# RZN2H register map
Vendor: Renesas Electronics Corporation; Series: RZN; File version: 1.00.00
CPU: other r0p0, little endian, MPU, no FPU, VTOR, 4 interrupt priority bits, 624 interrupts
Registers are 32-bit, read-write, reset 0x0 unless marked. A register's access mark holds for its fields unless they carry their own. Offsets are from the block's base; [hi:lo] are bit positions; {n}, {i} and the like mark numbered series.

## HDSLD0 — HIPERFACE DSL for Drive Interface Unit 0
Base 0x90200000
Same registers: HDSLD{n} {0x90200000+0x10000*n} (n=1..11), HDSLD12 0x90300000, HDSLD13 0x90310000, HDSLD14 0x90320000, HDSLD15 0x90330000
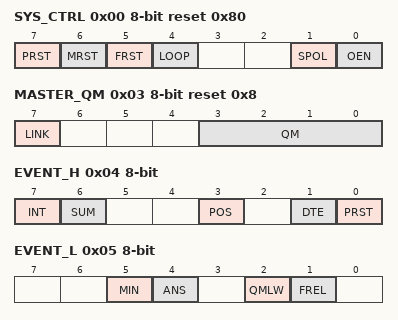
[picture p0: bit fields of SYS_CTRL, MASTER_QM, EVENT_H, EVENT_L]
0x00 SYS_CTRL 8-bit reset 0x80 — System Control Register
  [7] PRST — Protocol reset
    0=Normal protocol action; 1=A forced reset of the protocol status will be initiated. If the bit is cleared, a restart of the connection is triggered.
  [6] MRST — Messages reset
    0=Normal parameters channel action; 1=The parameters channel is reset. Current short and long messages are discarded.
  [5] FRST — Pipeline FIFO, reset
    0=Normal FIFO access; 1=The FIFO is reset. Data is not stored and cannot be read.
  [4] LOOP — Test drive interface
  [1] SPOL — Polarity of the synchronization pulse
    0=The SYNC trailing edge is used; 1=The SYNC leading edge is used
  [0] OEN — Activation of the output
    0=The impedance of the DSL cable is high; 1=The DSL cables are activated for output to the DSL Slave
0x01 SYNC_CTRL 8-bit wo — Synchronization Control Register
  [7:0] ES — External synchronization
    0=Position sampling during free running at the shortest cycle time; other=Others (Position sampling with the SYNC input synchronized. The value from ES determines the number of position samplings carried out in one SYNC cycle. The user must match the number of samplings per cycle to the shortest frame length.)
0x03 MASTER_QM 8-bit ro reset 0x8 — Quality Monitoring Register
  [7] LINK — DSL protocol connection status
    0=No connection present or connection error due to a communications error; 1=Protocol connection between DSL Master and Slave was established
  [3:0] QM — Quality monitoring bits
0x04 EVENT_H 8-bit — High Byte Event Register
  [7] INT ro — Interrupt status
    0=No interrupt in DSL Master; 1=DSL Master interrupt occurred
  [6] SUM — Remote event monitoring
    0=All DSL Slave events are cleared; 1=The DSL Slave has signaled an event and the summary mask is set accordingly
  [3] POS — Estimator turned on
    0=The data for the fast position was correctly transmitted; 1=Fast position data consistency error. The fast position read through drive interface is supplied by the estimator.
  [1] DTE — Estimator deviation threshold error
    0=Current value of deviation smaller than the specified maximum; 1=Current value of deviation greater than the specified maximum
  [0] PRST — Protocol reset warning
    0=Normal protocol action; 1=The forced protocol reset was triggered
0x05 EVENT_L 8-bit — Low Byte Event Register
  [5] MIN — Message initialization
    0=No acknowledgment for the initialization received; 1=An acknowledgment was received from the Slave for the initialization of a message
  [4] ANS — Erroneous answer to "long message"
    0=The last answers to "long messages" were error-free; 1=An error occurred during the answer to a long message. The effectiveness of the previous transaction is not known.
  [2] QMLW — Quality monitoring low-value warning
    0=Quality monitoring value greater than or equal to "14"; 1=Quality monitoring value below "14"
  [1] FREL — Channel free for "long message"
    0=No "long message" can be sent; 1=A "long message" can be sent on the Parameters Channel
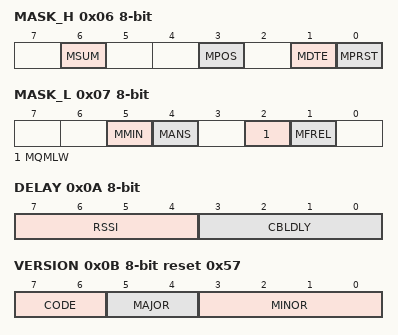
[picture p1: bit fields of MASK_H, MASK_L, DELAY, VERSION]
0x06 MASK_H 8-bit wo — High Byte Event Mask Register
  [6] MSUM — Mask for remote event monitoring
    0=DSL Slave events that are masked in the SUMMARY register do not set the interrupt signal; 1=DSL Slave events that are masked in the SUMMARY register set the interrupt signal
  [3] MPOS — Mask for fast position error
    0=An error in the fast position does not set the interrupt signal; 1=An error in the fast position sets the interrupt signal
  [1] MDTE — Mask for estimator deviation threshold error warning
    0=A high estimator deviation threshold error value does not set the interrupt signal; 1=A high estimator deviation threshold error value sets the interrupt signal
  [0] MPRST — Mask for protocol reset warning
    0=A protocol reset does not set the interrupt signal; 1=A protocol reset sets the interrupt signal
0x07 MASK_L 8-bit wo — Low Byte Event Mask Register
  [5] MMIN — Mask for message initialization confirmation
    0=The acknowledgment for the initialization of a DSL Slave message does not set the interrupt signal; 1=The acknowledgment for the initialization of a DSL Slave message sets the interrupt signal
  [4] MANS — Mask for erroneous answer to "long message"
    0=A transmission error during the answer to a long message does not set the interrupt signal; 1=A transmission error during the answer to a long message sets the interrupt signal
  [2] MQMLW — Mask for low-quality monitoring value warning
    0=A low-quality monitoring value does not set the interrupt signal; 1=A low-quality monitoring value sets the interrupt signal
  [1] MFREL — Mask for "channel free for "long message""
    0=If a "long message" can be sent on the Parameters Channel, the interrupt signal is not set; 1=If a "long message" can be sent on the Parameters Channel, the interrupt signal is set
0x08 MASK_SUM 8-bit wo — Summary Mask Register
  [7:0] MSUM — Mask for status summary bits
    0=In the set status, the corresponding status summary bit does not set the SUM event monitoring and the interrupt signal; 1=In the set status, the corresponding status summary bit sets the SUM event monitoring and the interrupt signal
0x09 EDGES 8-bit ro — Edge Register
  [7:0] EDGES — Identification of edges in the cable signal
0x0A DELAY 8-bit ro — Run Time Delay Register
  [7:4] RSSI — Indication of the received signal strength
  [3:0] CBLDLY — 4-bit value for cable delay
0x0B VERSION 8-bit ro reset 0x57
  [7:6] CODE — Type of module
    1=DSL Master; other=Others (Reserved)
  [5:4] MAJOR — Major release number
  [3:0] MINOR — Minor release number
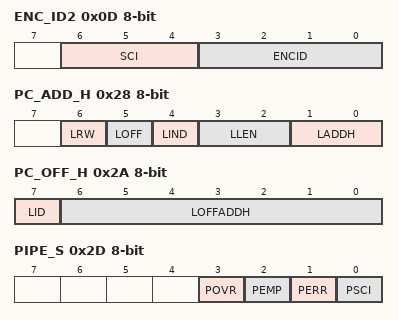
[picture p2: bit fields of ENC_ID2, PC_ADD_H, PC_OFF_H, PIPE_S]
0x0D ENC_ID2 8-bit ro — Encoder ID 2 Register
  [6:4] SCI — Indication of special characters
  [3:0] ENCID — Encoder designation code bit 19 to bit 16
0x0E ENC_ID1 8-bit ro — Encoder ID 1 Register
  [7:0] ENCID — Encoder designation code, byte n
0x0F ENC_ID0 8-bit ro — Encoder ID 0 Register
  [7:0] ENCID — Encoder designation code, byte n
0x10 POS4 8-bit ro — Fast Position Byte 4 Register
  [7:0] POS — Fast position, byte n
0x11 POS3 8-bit ro — Fast Position Byte 3 Register
  [7:0] POS — Fast position, byte n
0x12 POS2 8-bit ro — Fast Position Byte 2 Register
  [7:0] POS — Fast position, byte n
0x13 POS1 8-bit ro — Fast Position Byte 1 Register
  [7:0] POS — Fast position, byte n
0x14 POS0 8-bit ro — Fast Position Byte 0 Register
  [7:0] POS — Fast position, byte n
0x15 VEL2 8-bit ro — Speed Byte 2 Register
  [7:0] VEL — Speed, byte n
0x16 VEL1 8-bit ro — Speed Byte 1 Register
  [7:0] VEL — Speed, byte n
0x17 VEL0 8-bit ro — Speed Byte 0 Register
  [7:0] VEL — Speed, byte n
0x18 MIR_SUM 8-bit ro — Mirror Status Summary Register
  [7:0] SUM — Status summary bit
{0x20+i} PC_BUF{i} (i=0..7) 8-bit — Parameter Channel Buffer {i} Register
  [7:0] PCBUF — Parameter Channel, byte n
0x28 PC_ADD_H 8-bit — High Byte Long Message Address Register
  [6] LRW wo — Long message, read/write mode
    0="long message" write operation; 1="long message" read operation
  [5] LOFF — Long message addressing mode/long message error
    0=Write access: Addressing of "long message" without offset. The offset value from the PCOFFn registers is not used. Read access: The last "long message" was correctly processed.; 1=Write access: Offset addressing of "long message". The offset value from the PCOFFn registers is used in the resource of the selected database entry as a sub-address. Read access: The last "long message" caused an error.
  [4] LIND wo — Indirect addressing of long messages
    0=Direct addressing of "long messages". The operation affects the database entry given in the current address.; 1=Indirect addressing of "long messages". During this operation, the stored address content in the given database entry is evaluated.
  [3:2] LLEN wo — Data length of the "long message"
    0=No data bytes; 1=2 data bytes; 2=4 data bytes; 3=8 data bytes
  [1:0] LADDH wo — Long message address, bit 9 to bit 8
0x29 PC_ADD_L 8-bit wo — Low Byte Long Message Address Register
  [7:0] LADDL — Long message address, bit 7 to bit 0
0x2A PC_OFF_H 8-bit — High Byte Long Message Address Offset Register
  [7] LID ro — Long message identification
  [6:0] LOFFADDH wo — Long message offset value, bit 14 to bit 8
0x2B PC_OFF_L 8-bit wo — Low Byte Long Message Address Offset Register
  [7:0] LOFFADDL — Long message offset value, bit 7 to bit 0
0x2C PC_CTRL 8-bit wo — Parameter Channel Control Register
  [0] LSTA — Control of the long message start
    0=No effect; 1=A "long message" transaction is started with the values currently stored in the "long message" registers
0x2D PIPE_S 8-bit ro — SensorHub Channel Status Register
  [3] POVR — SensorHub Channel overflow
    0=The capacity of the FIFO buffer for SensorHub Channel data is not yet exhausted; 1=The capacity of the 8-byte FIFO buffer for SensorHub Channel data was exhausted and since the last read process, values have been discarded
  [2] PEMP — The SensorHub channel buffer is empty
    0=No "buffer empty" error; 1=A read request was issued, but the FIFO buffer for SensorHub Channel data is empty. In this case, PIPE_D contains the value 0x00.
  [1] PERR — Coding error of the bits in the SensorHub Channel
    0=No error in bit coding; 1=The bit level coding of the data currently in the SensorHub Channel is erroneous
  [0] PSCI — Indication for special characters in the SensorHub Channel
    0=Indication for "no special character"; 1=A special character was received in the SensorHub Channel
0x2E PIPE_D 8-bit ro — SensorHub Channel Data Register
  [7:0] SCDATA — SensorHub Channel data
0x2F PC_DATA 8-bit ro — Parameter Channel Short Message Mirror Register
  [7:0] PCDATA — "Short message" Mirror register data
0x38 ACC_ERR_CNT 8-bit — Fast Position Error Counter Register
  [4:0] CNT — Position error count/threshold
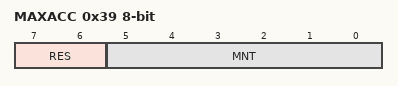
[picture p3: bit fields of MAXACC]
0x39 MAXACC 8-bit wo — Fast Position Acceleration Boundary Register
  [7:6] RES — Resolution of fast position acceleration boundary
  [5:0] MNT — Mantissa of fast position acceleration boundary
0x3A MAXDEV_H 8-bit reset 0xFF — Fast Position Estimator Deviation High Byte Register
  [7:0] DEVH — Fast position estimator deviation high byte
0x3B MAXDEV_L 8-bit reset 0xFF — Fast Position Estimator Deviation Low Byte Register
  [7:0] DEVL — Fast position estimator deviation low byte
0x3F DUMMY 8-bit ro reset not defined
  [7:0] DUMMY — Due to the transmission of the online-status, Online Status read transactions need less time for transmission. Therefore, dummy read transactions must be inserted to avoid unwanted extra transactions.
{0x60+i} MIR_ST{i} (i=0..7) 8-bit — Mirror Status {i} Register
  [7:0] MIRST — Mirror status, byte n
